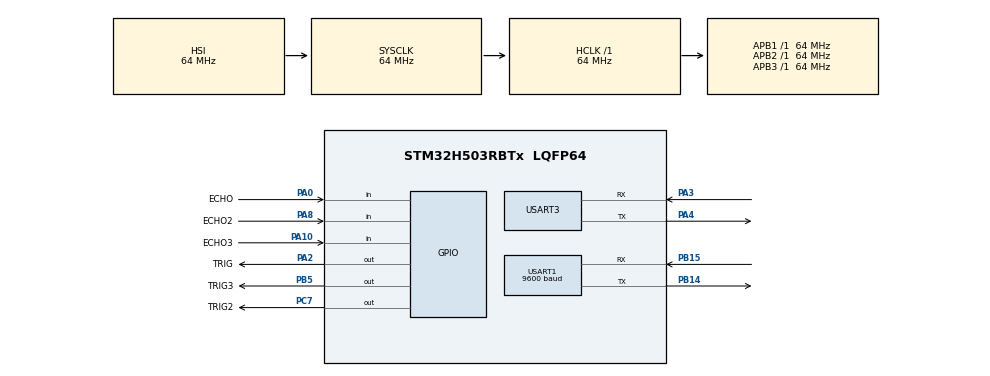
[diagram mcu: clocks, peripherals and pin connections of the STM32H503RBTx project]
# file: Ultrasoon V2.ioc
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BOOTPATH.BootPathName=LEGACY
BOOTPATH.UserSelectedBootPath=LEGACY
Mcu.Family=STM32H5
Mcu.Name=STM32H503RBTx
Mcu.Package=LQFP64
NVIC.PriorityGroup=NVIC_PRIORITYGROUP_4
PA0.GPIO_Label=ECHO
PA0.Signal=GPIO_Input
PA10.GPIO_Label=ECHO3
PA10.Signal=GPIO_Input
PA2.GPIO_Label=TRIG
PA2.Signal=GPIO_Output
PA3.Mode=Asynchronous
PA3.Signal=USART3_RX
PA4.Mode=Asynchronous
PA4.Signal=USART3_TX
PA8.GPIO_Label=ECHO2
PA8.Signal=GPIO_Input
PB14.Mode=Asynchronous
PB14.Signal=USART1_TX
PB15.Mode=Asynchronous
PB15.Signal=USART1_RX
PB5.GPIO_Label=TRIG3
PB5.Signal=GPIO_Output
PC7.GPIO_Label=TRIG2
PC7.Signal=GPIO_Output
ProjectManager.HeapSize=0x200
ProjectManager.StackSize=0x400
ProjectManager.TargetToolchain=STM32CubeIDE
RCC.ADCFreq_Value=64000000
RCC.AHBFreq_Value=64000000
RCC.APB1Freq_Value=64000000
RCC.APB1TimFreq_Value=64000000
RCC.APB2Freq_Value=64000000
RCC.APB2TimFreq_Value=64000000
RCC.APB3Freq_Value=64000000
RCC.CSI_VALUE=4000000
RCC.CortexFreq_Value=64000000
RCC.EPOD_VALUE=4000000
RCC.HCLKFreq_Value=64000000
RCC.HSE_VALUE=24000000
RCC.HSI48_VALUE=48000000
RCC.HSIDiv=RCC_HSI_DIV1
RCC.HSI_VALUE=64000000
RCC.LSE_VALUE=32768
RCC.LSIRC_VALUE=32000
RCC.PLLN=32
RCC.SYSCLKFreq_VALUE=64000000
RCC.USBFreq_Value=48000000
RCC.VCOOutputFreq_Value=128000000
TIM3.Prescaler=64 -1
USART1.BaudRate=9600
USART1.VirtualMode-Asynchronous=VM_ASYNC
USART3.VirtualMode-Asynchronous=VM_ASYNC
VP_BOOTPATH_VS_BOOTPATH.Mode=BP_Activate
VP_CORTEX_M33_NS_VS_Hclk.Mode=Hclk_Mode
VP_MEMORYMAP_VS_MEMORYMAP.Mode=CurAppReg
VP_PWR_VS_DBSignals.Mode=DisableDeadBatterySignals
VP_PWR_VS_LPOM.Mode=PowerOptimisation
VP_PWR_VS_SECSignals.Mode=Security/Privilege
VP_TIM3_VS_ClockSourceINT.Mode=Internal
board=NUCLEO-H503RB

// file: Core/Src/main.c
/* USER CODE BEGIN Header */
/**
  ******************************************************************************
  * @file           : main.c
  * @brief          : Main program body
  ******************************************************************************
  * @attention
  *
  * Copyright (c) 2024 STMicroelectronics.
  * All rights reserved.
  *
  * This software is licensed under terms that can be found in the LICENSE file
  * in the root directory of this software component.
  * If no LICENSE file comes with this software, it is provided AS-IS.
  *
  ******************************************************************************
  */
/* USER CODE END Header */
#include "main.h"

/* USER CODE BEGIN Includes */
#include <string.h>
#include <stdio.h>
#include "main_loop.hpp"
/* USER CODE END Includes */

/* USER CODE BEGIN PTD */
#define usTIM TIM3
/* USER CODE END PTD */

TIM_HandleTypeDef htim3;

UART_HandleTypeDef huart1;
UART_HandleTypeDef huart3;

void SystemClock_Config(void);
static void MX_GPIO_Init(void);
static void MX_TIM3_Init(void);
static void MX_USART3_UART_Init(void);
static void MX_USART1_UART_Init(void);
/* USER CODE BEGIN PFP */
void usDelay(uint32_t uSec);
/* USER CODE END PFP */

int main(void)
{

  /* MCU Configuration--------------------------------------------------------*/

  /* Reset of all peripherals, Initializes the Flash interface and the Systick. */
  HAL_Init();

  /* Configure the system clock */
  SystemClock_Config();

  /* Initialize all configured peripherals */
  MX_GPIO_Init();
  MX_TIM3_Init();
  MX_USART3_UART_Init();
  MX_USART1_UART_Init();

  /* Infinite loop */
  while (1)
  {
	  main_loop_c();
  }
}

void SystemClock_Config(void)
{
  RCC_OscInitTypeDef RCC_OscInitStruct = {0};
  RCC_ClkInitTypeDef RCC_ClkInitStruct = {0};

  /** Configure the main internal regulator output voltage
  */
  __HAL_PWR_VOLTAGESCALING_CONFIG(PWR_REGULATOR_VOLTAGE_SCALE3);

  while(!__HAL_PWR_GET_FLAG(PWR_FLAG_VOSRDY)) {}

  /** Initializes the RCC Oscillators according to the specified parameters
  * in the RCC_OscInitTypeDef structure.
  */
  RCC_OscInitStruct.OscillatorType = RCC_OSCILLATORTYPE_HSI;
  RCC_OscInitStruct.HSIState = RCC_HSI_ON;
  RCC_OscInitStruct.HSIDiv = RCC_HSI_DIV1;
  RCC_OscInitStruct.HSICalibrationValue = RCC_HSICALIBRATION_DEFAULT;
  RCC_OscInitStruct.PLL.PLLState = RCC_PLL_NONE;
  if (HAL_RCC_OscConfig(&RCC_OscInitStruct) != HAL_OK)
  {
    Error_Handler();
  }

  /** Initializes the CPU, AHB and APB buses clocks
  */
  RCC_ClkInitStruct.ClockType = RCC_CLOCKTYPE_HCLK|RCC_CLOCKTYPE_SYSCLK
                              |RCC_CLOCKTYPE_PCLK1|RCC_CLOCKTYPE_PCLK2
                              |RCC_CLOCKTYPE_PCLK3;
  RCC_ClkInitStruct.SYSCLKSource = RCC_SYSCLKSOURCE_HSI;
  RCC_ClkInitStruct.AHBCLKDivider = RCC_SYSCLK_DIV1;
  RCC_ClkInitStruct.APB1CLKDivider = RCC_HCLK_DIV1;
  RCC_ClkInitStruct.APB2CLKDivider = RCC_HCLK_DIV1;
  RCC_ClkInitStruct.APB3CLKDivider = RCC_HCLK_DIV1;

  if (HAL_RCC_ClockConfig(&RCC_ClkInitStruct, FLASH_LATENCY_3) != HAL_OK)
  {
    Error_Handler();
  }

  /** Configure the programming delay
  */
  __HAL_FLASH_SET_PROGRAM_DELAY(FLASH_PROGRAMMING_DELAY_1);
}

static void MX_TIM3_Init(void)
{

  TIM_ClockConfigTypeDef sClockSourceConfig = {0};
  TIM_MasterConfigTypeDef sMasterConfig = {0};

  htim3.Instance = TIM3;
  htim3.Init.Prescaler = 64 -1;
  htim3.Init.CounterMode = TIM_COUNTERMODE_UP;
  htim3.Init.Period = 65535;
  htim3.Init.ClockDivision = TIM_CLOCKDIVISION_DIV1;
  htim3.Init.AutoReloadPreload = TIM_AUTORELOAD_PRELOAD_DISABLE;
  if (HAL_TIM_Base_Init(&htim3) != HAL_OK)
  {
    Error_Handler();
  }
  sClockSourceConfig.ClockSource = TIM_CLOCKSOURCE_INTERNAL;
  if (HAL_TIM_ConfigClockSource(&htim3, &sClockSourceConfig) != HAL_OK)
  {
    Error_Handler();
  }
  sMasterConfig.MasterOutputTrigger = TIM_TRGO_RESET;
  sMasterConfig.MasterSlaveMode = TIM_MASTERSLAVEMODE_DISABLE;
  if (HAL_TIMEx_MasterConfigSynchronization(&htim3, &sMasterConfig) != HAL_OK)
  {
    Error_Handler();
  }

}

static void MX_USART1_UART_Init(void)
{

  huart1.Instance = USART1;
  huart1.Init.BaudRate = 9600;
  huart1.Init.WordLength = UART_WORDLENGTH_8B;
  huart1.Init.StopBits = UART_STOPBITS_1;
  huart1.Init.Parity = UART_PARITY_NONE;
  huart1.Init.Mode = UART_MODE_TX_RX;
  huart1.Init.HwFlowCtl = UART_HWCONTROL_NONE;
  huart1.Init.OverSampling = UART_OVERSAMPLING_16;
  huart1.Init.OneBitSampling = UART_ONE_BIT_SAMPLE_DISABLE;
  huart1.Init.ClockPrescaler = UART_PRESCALER_DIV1;
  huart1.AdvancedInit.AdvFeatureInit = UART_ADVFEATURE_NO_INIT;
  if (HAL_UART_Init(&huart1) != HAL_OK)
  {
    Error_Handler();
  }
  if (HAL_UARTEx_SetTxFifoThreshold(&huart1, UART_TXFIFO_THRESHOLD_1_8) != HAL_OK)
  {
    Error_Handler();
  }
  if (HAL_UARTEx_SetRxFifoThreshold(&huart1, UART_RXFIFO_THRESHOLD_1_8) != HAL_OK)
  {
    Error_Handler();
  }
  if (HAL_UARTEx_DisableFifoMode(&huart1) != HAL_OK)
  {
    Error_Handler();
  }

}

static void MX_USART3_UART_Init(void)
{

  huart3.Instance = USART3;
  huart3.Init.BaudRate = 115200;
  huart3.Init.WordLength = UART_WORDLENGTH_8B;
  huart3.Init.StopBits = UART_STOPBITS_1;
  huart3.Init.Parity = UART_PARITY_NONE;
  huart3.Init.Mode = UART_MODE_TX_RX;
  huart3.Init.HwFlowCtl = UART_HWCONTROL_NONE;
  huart3.Init.OverSampling = UART_OVERSAMPLING_16;
  huart3.Init.OneBitSampling = UART_ONE_BIT_SAMPLE_DISABLE;
  huart3.Init.ClockPrescaler = UART_PRESCALER_DIV1;
  huart3.AdvancedInit.AdvFeatureInit = UART_ADVFEATURE_NO_INIT;
  if (HAL_UART_Init(&huart3) != HAL_OK)
  {
    Error_Handler();
  }
  if (HAL_UARTEx_SetTxFifoThreshold(&huart3, UART_TXFIFO_THRESHOLD_1_8) != HAL_OK)
  {
    Error_Handler();
  }
  if (HAL_UARTEx_SetRxFifoThreshold(&huart3, UART_RXFIFO_THRESHOLD_1_8) != HAL_OK)
  {
    Error_Handler();
  }
  if (HAL_UARTEx_DisableFifoMode(&huart3) != HAL_OK)
  {
    Error_Handler();
  }

}

static void MX_GPIO_Init(void)
{
  GPIO_InitTypeDef GPIO_InitStruct = {0};

  /* GPIO Ports Clock Enable */
  __HAL_RCC_GPIOA_CLK_ENABLE();
  __HAL_RCC_GPIOB_CLK_ENABLE();
  __HAL_RCC_GPIOC_CLK_ENABLE();

  /*Configure GPIO pin Output Level */
  HAL_GPIO_WritePin(TRIG_GPIO_Port, TRIG_Pin, GPIO_PIN_RESET);

  /*Configure GPIO pin Output Level */
  HAL_GPIO_WritePin(TRIG2_GPIO_Port, TRIG2_Pin, GPIO_PIN_RESET);

  /*Configure GPIO pin Output Level */
  HAL_GPIO_WritePin(TRIG3_GPIO_Port, TRIG3_Pin, GPIO_PIN_RESET);

  /*Configure GPIO pins : ECHO_Pin ECHO2_Pin ECHO3_Pin */
  GPIO_InitStruct.Pin = ECHO_Pin|ECHO2_Pin|ECHO3_Pin;
  GPIO_InitStruct.Mode = GPIO_MODE_INPUT;
  GPIO_InitStruct.Pull = GPIO_NOPULL;
  HAL_GPIO_Init(GPIOA, &GPIO_InitStruct);

  /*Configure GPIO pin : TRIG_Pin */
  GPIO_InitStruct.Pin = TRIG_Pin;
  GPIO_InitStruct.Mode = GPIO_MODE_OUTPUT_PP;
  GPIO_InitStruct.Pull = GPIO_NOPULL;
  GPIO_InitStruct.Speed = GPIO_SPEED_FREQ_LOW;
  HAL_GPIO_Init(TRIG_GPIO_Port, &GPIO_InitStruct);

  /*Configure GPIO pin : TRIG2_Pin */
  GPIO_InitStruct.Pin = TRIG2_Pin;
  GPIO_InitStruct.Mode = GPIO_MODE_OUTPUT_PP;
  GPIO_InitStruct.Pull = GPIO_NOPULL;
  GPIO_InitStruct.Speed = GPIO_SPEED_FREQ_LOW;
  HAL_GPIO_Init(TRIG2_GPIO_Port, &GPIO_InitStruct);

  /*Configure GPIO pin : TRIG3_Pin */
  GPIO_InitStruct.Pin = TRIG3_Pin;
  GPIO_InitStruct.Mode = GPIO_MODE_OUTPUT_PP;
  GPIO_InitStruct.Pull = GPIO_NOPULL;
  GPIO_InitStruct.Speed = GPIO_SPEED_FREQ_LOW;
  HAL_GPIO_Init(TRIG3_GPIO_Port, &GPIO_InitStruct);

}

/* USER CODE BEGIN 4 */
void usDelay(uint32_t uSec)
{
	if(uSec < 2) uSec = 2;
	usTIM->ARR = uSec - 1; 	/*sets the value in the auto-reload register*/
	usTIM->EGR = 1; 			/*Re-initialises the timer*/
	usTIM->SR &= ~1; 		//Resets the flag
	usTIM->CR1 |= 1; 		//Enables the counter
	while((usTIM->SR&0x0001) != 1);
	usTIM->SR &= ~(0x0001);
}
/* USER CODE END 4 */

void Error_Handler(void)
{
  __disable_irq();
  while (1)
  {
  }
}
